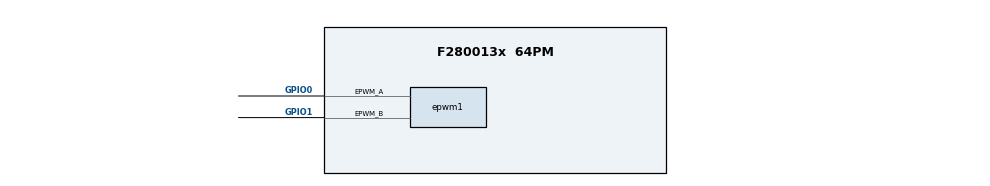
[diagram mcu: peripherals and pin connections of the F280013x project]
/**
 * @cliArgs --device "F280013x" --part "F280013x_64PM" --package "64PM" --context "system" --product "C2000WARE@6.00.00.00"
 * @versions {"tool":"1.24.0+4110"}
 */

/**
 * Import the modules used in this configuration.
 */
const epwm  = scripting.addModule("/driverlib/epwm.js", {}, false);
const epwm1 = epwm.addInstance();

/**
 * Write custom configuration values to the imported modules.
 */
epwm1.$name                                                      = "myEPWM0";
epwm1.epwmTimebase_clockDiv                                      = "EPWM_CLOCK_DIVIDER_4";
epwm1.epwmTimebase_hsClockDiv                                    = "EPWM_HSCLOCK_DIVIDER_4";
epwm1.epwmTimebase_period                                        = 2000;
epwm1.epwmTimebase_counterMode                                   = "EPWM_COUNTER_MODE_UP_DOWN";
epwm1.epwmCounterCompare_cmpA                                    = 500;
epwm1.epwmActionQualifier_EPWM_AQ_OUTPUT_A_ON_TIMEBASE_ZERO      = "EPWM_AQ_OUTPUT_LOW";
epwm1.epwmActionQualifier_EPWM_AQ_OUTPUT_A_ON_TIMEBASE_UP_CMPA   = "EPWM_AQ_OUTPUT_HIGH";
epwm1.epwmActionQualifier_EPWM_AQ_OUTPUT_A_ON_TIMEBASE_DOWN_CMPA = "EPWM_AQ_OUTPUT_LOW";
epwm1.epwmActionQualifier_EPWM_AQ_OUTPUT_B_ON_TIMEBASE_ZERO      = "EPWM_AQ_OUTPUT_LOW";
epwm1.epwmActionQualifier_EPWM_AQ_OUTPUT_B_ON_TIMEBASE_UP_CMPB   = "EPWM_AQ_OUTPUT_HIGH";
epwm1.epwmActionQualifier_EPWM_AQ_OUTPUT_B_ON_TIMEBASE_DOWN_CMPB = "EPWM_AQ_OUTPUT_LOW";
epwm1.epwmCounterCompare_cmpB                                    = 1000;
epwm1.epwm.$assign                                               = "EPWM1";
epwm1.epwm.epwm_aPin.$assign                                     = "GPIO0";
epwm1.epwm.epwm_bPin.$assign                                     = "GPIO1";
